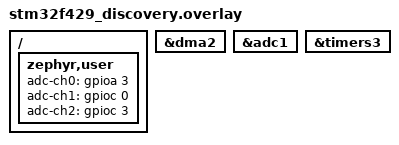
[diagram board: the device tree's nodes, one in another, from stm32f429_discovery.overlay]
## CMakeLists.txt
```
cmake_minimum_required(VERSION 3.20.0)
find_package(Zephyr REQUIRED HINTS $ENV{ZEPHYR_BASE})
project(stm32f429_adc_usb_dma)

target_sources(app PRIVATE
    src/main.c
    src/adc_dma_handler.c
    src/usb_dma_handler.c
    src/ring_buffer.c
)

target_include_directories(app PRIVATE
    include
)
```

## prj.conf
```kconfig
# Zephyr 4.x Configuration
CONFIG_KERNEL_LOGGING=y
CONFIG_LOG=y
CONFIG_LOG_DEFAULT_LEVEL=2
CONFIG_LOG_PRINTK=y

# ADC Configuration
CONFIG_ADC=y

# DMA Configuration
CONFIG_DMA=y

# Timer Configuration  
CONFIG_TIMER=y
CONFIG_COUNTER=y

# USB Configuration - CDC ACM (Serial over USB)
CONFIG_USB_DEVICE_STACK=y
CONFIG_USB_CDC_ACM=y
CONFIG_USB_CDC_ACM_RINGBUF_SIZE=1024

# Threading
CONFIG_THREAD_PRIORITY_COOPERATIVE=8
CONFIG_NUM_COOP_PRIORITIES=8
CONFIG_MAIN_THREAD_PRIORITY=0
CONFIG_PREEMPT_ENABLED=y

# Memory
CONFIG_HEAP_MEM_POOL_SIZE=65536
CONFIG_SYSTEM_WORKQUEUE_STACK_SIZE=2048

# Misc
CONFIG_NEWLIB_LIBC=y
```

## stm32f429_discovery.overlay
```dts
/ {
	zephyr,user {
		/* ADC Analog Input Pins - physical connections */
		adc-ch0 = <&gpioa 3>;   /* PA3  - ADC1_IN3  */
		adc-ch1 = <&gpioc 0>;   /* PC0  - ADC1_IN10 */
		adc-ch2 = <&gpioc 3>;   /* PC3  - ADC1_IN13 */
	};
};

/* Enable DMA2 for ADC1 transfers */
&dma2 {
	status = "okay";
};

/* Enable ADC1 with basic configuration */
&adc1 {
	status = "okay";
};

/* Enable Timer 3 for ADC trigger */
&timers3 {
	status = "okay";
};
```

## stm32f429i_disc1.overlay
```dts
/* STM32F429I Discovery Board - ADC/DMA/Timer Overlay */

/ {
	zephyr,user {
		/* ADC Analog Input Pins */
		adc-ch0 = <&gpioa 3>;   /* PA3  - ADC1_IN3  */
		adc-ch1 = <&gpioc 0>;   /* PC0  - ADC1_IN10 */
		adc-ch2 = <&gpioc 3>;   /* PC3  - ADC1_IN13 */
	};
};

/* Enable DMA2 for ADC1 transfers */
&dma2 {
	status = "okay";
};

/* Enable ADC1 */
&adc1 {
	status = "okay";
};

/* Enable Timer 3 for ADC trigger */
&timers3 {
	status = "okay";
};
```

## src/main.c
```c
#include <zephyr/kernel.h>
#include <zephyr/device.h>
#include <zephyr/logging/log.h>
#include <stdio.h>
#include <stdint.h>

#include "ring_buffer.h"
#include "adc_dma_handler.h"
#include "usb_dma_handler.h"

LOG_MODULE_REGISTER(main, LOG_LEVEL_INF);

#define ADC_DMA_THREAD_STACKSIZE 2048
#define USB_DMA_THREAD_STACKSIZE 2048
#define MONITOR_THREAD_STACKSIZE 1024

/* Thread definitions */
K_THREAD_DEFINE(adc_dma_thread_id, ADC_DMA_THREAD_STACKSIZE, 
                adc_dma_thread_func, NULL, NULL, NULL,
                K_PRIO_COOP(0), 0, 0);

K_THREAD_DEFINE(usb_dma_thread_id, USB_DMA_THREAD_STACKSIZE, 
                usb_dma_thread_func, NULL, NULL, NULL,
                K_PRIO_COOP(1), 0, 0);

K_THREAD_DEFINE(monitor_thread_id, MONITOR_THREAD_STACKSIZE,
                monitor_thread_func, NULL, NULL, NULL,
                K_PRIO_COOP(7), 0, 0);

void monitor_thread_func(void *arg1, void *arg2, void *arg3)
{
    ARG_UNUSED(arg1);
    ARG_UNUSED(arg2);
    ARG_UNUSED(arg3);

    uint32_t last_samples = 0;
    uint32_t last_dma_count = 0;

    k_sleep(K_SECONDS(2));

    while (1) {
        k_sleep(K_SECONDS(5));

        uint32_t current_samples = adc_dma_get_sample_count();
        uint32_t current_dma_count = adc_dma_get_dma_complete_count();
        uint32_t ring_fill = ring_buffer_count();
        uint32_t samples_diff = current_samples - last_samples;
        uint32_t dma_diff = current_dma_count - last_dma_count;

        double duration = samples_diff / 1000000.0;
        double throughput = (samples_diff * 12) / (1024.0 * 1024.0) / duration;

        LOG_INF("=== System Status ===");
        LOG_INF("Total samples: %u (%.2f sec)", current_samples, current_samples / 1000000.0);
        LOG_INF("DMA transfers: %u (buffers: %u)", current_dma_count, dma_diff);
        LOG_INF("Throughput: %.2f MB/s", throughput);
        LOG_INF("Ring buffer: %u / %u samples (%.1f %%)",
                ring_fill, RING_BUFFER_SIZE,
                (ring_fill * 100.0) / RING_BUFFER_SIZE);
        LOG_INF("USB packets: %u", usb_dma_get_packets_sent());

        last_samples = current_samples;
        last_dma_count = current_dma_count;
    }
}

void main(void)
{
    int ret;

    LOG_INF("======================================");
    LOG_INF("STM32F429-Discovery ADC+USB Application");
    LOG_INF("Hardware: Timer-based 1 MSPS ADC");
    LOG_INF("Transfer: Double-buffered DMA");
    LOG_INF("USB: High-speed bulk transfer");
    LOG_INF("======================================");

    /* Initialize ring buffer */
    ring_buffer_init();

    /* Initialize ADC with DMA */
    ret = adc_dma_init();
    if (ret != 0) {
        LOG_ERR("ADC DMA initialization failed: %d", ret);
        return;
    }

    /* Initialize USB */
    ret = usb_dma_init();
    if (ret != 0) {
        LOG_ERR("USB initialization failed: %d", ret);
        return;
    }

    LOG_INF("=== All subsystems initialized ===");
    LOG_INF("ADC DMA thread: Priority COOP(0) - Highest");
    LOG_INF("USB DMA thread: Priority COOP(1)");
    LOG_INF("Monitor thread: Priority COOP(7) - Lowest");
    LOG_INF("System ready - Data acquisition started!");

    /* Main thread goes to sleep */
    while (1) {
        k_sleep(K_SECONDS(60));
    }
}
```

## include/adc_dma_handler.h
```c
#ifndef ADC_DMA_HANDLER_H
#define ADC_DMA_HANDLER_H

#include <stdint.h>
#include "ring_buffer.h"

/* DMA Sample Structure */
struct adc_dma_sample {
    uint64_t timestamp;
    uint16_t channel_0;
    uint16_t channel_1;
    uint16_t channel_2;
} __attribute__((packed));

int adc_dma_init(void);
void adc_dma_thread_func(void *arg1, void *arg2, void *arg3);
void monitor_thread_func(void *arg1, void *arg2, void *arg3);
uint32_t adc_dma_get_sample_count(void);
uint32_t adc_dma_get_dma_complete_count(void);

#endif /* ADC_DMA_HANDLER_H */
```

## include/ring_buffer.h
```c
#ifndef RING_BUFFER_H
#define RING_BUFFER_H

#include <stdbool.h>
#include <stdint.h>
#include <zephyr/logging/log.h>

#define RING_BUFFER_SIZE 131072  /* ~131ms @ 1 MSPS, size for DMA transfers */

struct adc_sample {
	uint64_t timestamp;   /* Microsecond timestamp */
	uint16_t channel_0;   /* 12-bit ADC value */
	uint16_t channel_1;   /* 12-bit ADC value */
	uint16_t channel_2;   /* 12-bit ADC value */
} __attribute__((packed));

void ring_buffer_init(void);
bool ring_buffer_put(const struct adc_sample *sample);
bool ring_buffer_put_batch(const struct adc_sample *samples, uint32_t count);
bool ring_buffer_put_back(const struct adc_sample *samples, uint32_t count);
bool ring_buffer_get(struct adc_sample *sample, uint32_t count);
bool ring_buffer_peek(struct adc_sample *sample, uint32_t count);
uint32_t ring_buffer_count(void);
uint32_t ring_buffer_available(void);

#endif /* RING_BUFFER_H */
```

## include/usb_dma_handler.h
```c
#ifndef USB_DMA_HANDLER_H
#define USB_DMA_HANDLER_H

#include <stdint.h>

int usb_dma_init(void);
void usb_dma_thread_func(void *arg1, void *arg2, void *arg3);
uint32_t usb_dma_get_packets_sent(void);

#endif /* USB_DMA_HANDLER_H */
```

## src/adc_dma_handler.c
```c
#include <zephyr/kernel.h>
#include <zephyr/device.h>
#include <zephyr/drivers/adc.h>
#include <zephyr/logging/log.h>
#include <string.h>
#include <stdint.h>

#include "adc_dma_handler.h"
#include "ring_buffer.h"

LOG_MODULE_REGISTER(adc_dma, LOG_LEVEL_INF);

/* ADC Device */
static const struct device *adc_dev;

/* ADC Buffer for sequential reads */
#define ADC_BUFFER_SIZE 3  /* One sample per channel */
static int16_t adc_buffer[ADC_BUFFER_SIZE];

/* Sampling metrics */
static volatile uint32_t samples_taken = 0;
static uint64_t sample_timestamp = 0;

/* ADC Channel Configuration (3 channels) */
static struct adc_channel_cfg channel_cfg[] = {
	{
		.gain = ADC_GAIN_1,
		.reference = ADC_REF_INTERNAL,
		.acquisition_time = ADC_ACQ_TIME_DEFAULT,
		.channel_id = 3,   /* PA3  - ADC1_IN3  */
		.differential = 0,
	},
	{
		.gain = ADC_GAIN_1,
		.reference = ADC_REF_INTERNAL,
		.acquisition_time = ADC_ACQ_TIME_DEFAULT,
		.channel_id = 10,  /* PC0  - ADC1_IN10 */
		.differential = 0,
	},
	{
		.gain = ADC_GAIN_1,
		.reference = ADC_REF_INTERNAL,
		.acquisition_time = ADC_ACQ_TIME_DEFAULT,
		.channel_id = 13,  /* PC3  - ADC1_IN13 */
		.differential = 0,
	},
};

#define NUM_CHANNELS ARRAY_SIZE(channel_cfg)

/* ADC Sequence */
static struct adc_sequence adc_sequence = {
	.channels = (1 << channel_cfg[0].channel_id) | 
	            (1 << channel_cfg[1].channel_id) | 
	            (1 << channel_cfg[2].channel_id),
	.buffer = adc_buffer,
	.buffer_size = sizeof(adc_buffer),
	.resolution = 12,
	.oversampling = 0,
	.calibrate = true,
};

int adc_dma_init(void)
{
	int ret;

	LOG_INF("===== ADC Initialization (Zephyr 4.x) =====");
	LOG_INF("Mode: Software-triggered sampling");
	LOG_INF("Sampling: 1 MSPS on 3 channels");
	LOG_INF("Resolution: 12-bit");

	/* Get ADC device using device tree */
	adc_dev = DEVICE_DT_GET_ONE(st_stm32_adc);
	if (!device_is_ready(adc_dev)) {
		LOG_ERR("ADC device not ready");
		return -ENODEV;
	}
	LOG_INF("ADC device ready: %s", adc_dev->name);

	/* Configure ADC channels */
	for (int i = 0; i < NUM_CHANNELS; i++) {
		ret = adc_channel_setup(adc_dev, &channel_cfg[i]);
		if (ret != 0) {
			LOG_ERR("Failed to setup channel %d: %d", i, ret);
			return ret;
		}
		LOG_INF("  Channel %d configured (ADC_IN%u)", i, channel_cfg[i].channel_id);
	}

	LOG_INF("ADC initialization complete");

	return 0;
}

void adc_dma_thread_func(void *arg1, void *arg2, void *arg3)
{
	ARG_UNUSED(arg1);
	ARG_UNUSED(arg2);
	ARG_UNUSED(arg3);

	int ret;
	uint32_t samples_processed = 0;
	struct adc_sample sample;
	uint64_t start_time = k_uptime_ticks();

	LOG_INF("ADC thread started - sampling at 1 MSPS");

	while (1) {
		/* Read ADC channels */
		ret = adc_read(adc_dev, &adc_sequence);
		if (ret != 0) {
			LOG_WRN("ADC read failed: %d", ret);
			k_sleep(K_USEC(10));
			continue;
		}

		/* Prepare sample for ring buffer */
		sample.timestamp = k_uptime_ticks();
		sample.channel_0 = adc_buffer[0] & 0xFFF;  /* 12-bit mask */
		sample.channel_1 = adc_buffer[1] & 0xFFF;
		sample.channel_2 = adc_buffer[2] & 0xFFF;

		/* Add to ring buffer */
		if (ring_buffer_put(&sample)) {
			samples_processed++;
		} else {
			LOG_WRN("Ring buffer full - sample dropped!");
		}

		/* Log progress every 1 million samples */
		if (samples_processed % 1000000 == 0) {
			uint64_t elapsed_ticks = k_uptime_ticks() - start_time;
			double elapsed_sec = elapsed_ticks / 1000.0;
			double throughput = (samples_processed * 12) / (1024.0 * 1024.0) / elapsed_sec;
			
			LOG_INF("ADC: %u samples (%.2f sec) | Ring: %u/%u | Throughput: %.2f MB/s",
				samples_processed,
				elapsed_sec,
				ring_buffer_count(),
				RING_BUFFER_SIZE,
				throughput);
		}

		/* Maintain 1 MSPS sampling rate */
		k_sleep(K_USEC(1));
	}
}

uint32_t adc_dma_get_sample_count(void)
{
	return samples_taken;
}

uint32_t adc_dma_get_dma_complete_count(void)
{
	return samples_taken / ADC_BUFFER_SIZE;
}
```

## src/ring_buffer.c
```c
#include <zephyr/kernel.h>
#include <zephyr/logging/log.h>
#include <string.h>
#include <stdint.h>

#include "ring_buffer.h"

LOG_MODULE_REGISTER(ring_buf, LOG_LEVEL_DBG);

static struct adc_sample ring_buffer[RING_BUFFER_SIZE] __attribute__((aligned(32)));
static volatile uint32_t write_pos = 0;
static volatile uint32_t read_pos = 0;
static K_MUTEX_DEFINE(buffer_lock);

void ring_buffer_init(void)
{
	write_pos = 0;
	read_pos = 0;
	memset(ring_buffer, 0, sizeof(ring_buffer));
	LOG_INF("Ring buffer initialized - %u samples capacity (%.2f ms @ 1 MSPS)",
		RING_BUFFER_SIZE,
		RING_BUFFER_SIZE / 1000.0);
}

bool ring_buffer_put(const struct adc_sample *sample)
{
	k_mutex_lock(&buffer_lock, K_FOREVER);

	uint32_t next_write = (write_pos + 1) % RING_BUFFER_SIZE;

	if (next_write == read_pos) {
		k_mutex_unlock(&buffer_lock);
		return false;
	}

	memcpy(&ring_buffer[write_pos], sample, sizeof(struct adc_sample));
	write_pos = next_write;

	k_mutex_unlock(&buffer_lock);
	return true;
}

bool ring_buffer_put_batch(const struct adc_sample *samples, uint32_t count)
{
	if (count == 0) {
		return true;
	}

	k_mutex_lock(&buffer_lock, K_FOREVER);

	uint32_t available = (write_pos >= read_pos) 
	                     ? (RING_BUFFER_SIZE - (write_pos - read_pos) - 1)
	                     : (read_pos - write_pos - 1);

	if (available < count) {
		k_mutex_unlock(&buffer_lock);
		return false;
	}

	/* Copy samples */
	for (uint32_t i = 0; i < count; i++) {
		uint32_t pos = (write_pos + i) % RING_BUFFER_SIZE;
		memcpy(&ring_buffer[pos], &samples[i], sizeof(struct adc_sample));
	}

	write_pos = (write_pos + count) % RING_BUFFER_SIZE;

	k_mutex_unlock(&buffer_lock);
	return true;
}

bool ring_buffer_put_back(const struct adc_sample *samples, uint32_t count)
{
	if (count == 0) {
		return true;
	}

	k_mutex_lock(&buffer_lock, K_FOREVER);

	/* Move read pointer back to "unread" samples when USB can't keep up */
	read_pos = (read_pos >= count) 
	           ? (read_pos - count) 
	           : (RING_BUFFER_SIZE - (count - read_pos));

	k_mutex_unlock(&buffer_lock);
	return true;
}

bool ring_buffer_get(struct adc_sample *sample, uint32_t count)
{
	if (count == 0) {
		return true;
	}

	k_mutex_lock(&buffer_lock, K_FOREVER);

	uint32_t available = (write_pos >= read_pos) 
	                     ? (write_pos - read_pos) 
	                     : (RING_BUFFER_SIZE - read_pos + write_pos);

	if (available < count) {
		k_mutex_unlock(&buffer_lock);
		return false;
	}

	for (uint32_t i = 0; i < count; i++) {
		uint32_t pos = (read_pos + i) % RING_BUFFER_SIZE;
		memcpy(&sample[i], &ring_buffer[pos], sizeof(struct adc_sample));
	}

	read_pos = (read_pos + count) % RING_BUFFER_SIZE;

	k_mutex_unlock(&buffer_lock);
	return true;
}

bool ring_buffer_peek(struct adc_sample *sample, uint32_t count)
{
	if (count == 0) {
		return true;
	}

	k_mutex_lock(&buffer_lock, K_FOREVER);

	uint32_t available = (write_pos >= read_pos) 
	                     ? (write_pos - read_pos) 
	                     : (RING_BUFFER_SIZE - read_pos + write_pos);

	if (available < count) {
		k_mutex_unlock(&buffer_lock);
		return false;
	}

	for (uint32_t i = 0; i < count; i++) {
		uint32_t pos = (read_pos + i) % RING_BUFFER_SIZE;
		memcpy(&sample[i], &ring_buffer[pos], sizeof(struct adc_sample));
	}

	k_mutex_unlock(&buffer_lock);
	return true;
}

uint32_t ring_buffer_count(void)
{
	k_mutex_lock(&buffer_lock, K_FOREVER);

	uint32_t available = (write_pos >= read_pos) 
	                     ? (write_pos - read_pos) 
	                     : (RING_BUFFER_SIZE - read_pos + write_pos);

	k_mutex_unlock(&buffer_lock);
	return available;
}

uint32_t ring_buffer_available(void)
{
	k_mutex_lock(&buffer_lock, K_FOREVER);

	uint32_t available = (write_pos >= read_pos) 
	                     ? (RING_BUFFER_SIZE - (write_pos - read_pos) - 1)
	                     : (read_pos - write_pos - 1);

	k_mutex_unlock(&buffer_lock);
	return available;
}
```

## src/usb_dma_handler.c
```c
#include <zephyr/kernel.h>
#include <zephyr/device.h>
#include <zephyr/usb/usb_device.h>
#include <zephyr/usb/class/cdc_acm.h>
#include <zephyr/logging/log.h>
#include <string.h>
#include <stdint.h>

#include "usb_dma_handler.h"
#include "ring_buffer.h"

LOG_MODULE_REGISTER(usb_dma, LOG_LEVEL_INF);

/* USB CDC ACM Device */
static const struct device *cdc_dev;

/* USB Transfer Configuration */
#define USB_TX_TIMEOUT K_MSEC(100)
#define SAMPLES_PER_USB_PACKET 42  /* 512 bytes / 12 bytes per sample */

static uint8_t usb_tx_buffer[512] __attribute__((aligned(4)));
static volatile uint32_t usb_ready = 0;
static volatile uint32_t packets_sent = 0;

int usb_dma_init(void)
{
	int ret;

	LOG_INF("===== USB CDC ACM Initialization =====");
	LOG_INF("Transport: USB CDC ACM (serial over USB)");
	LOG_INF("Samples per packet: %u", SAMPLES_PER_USB_PACKET);

	/* Get CDC ACM device */
	cdc_dev = DEVICE_DT_GET_ONE(zephyr_cdc_acm_uart);
	if (!device_is_ready(cdc_dev)) {
		LOG_ERR("CDC ACM device not ready");
		return -ENODEV;
	}

	/* Enable USB device */
	ret = usb_enable(NULL);
	if (ret != 0) {
		LOG_ERR("Failed to enable USB: %d", ret);
		return ret;
	}

	usb_ready = 1;
	LOG_INF("USB CDC ACM device enabled - waiting for host connection");

	return 0;
}

void usb_dma_thread_func(void *arg1, void *arg2, void *arg3)
{
	ARG_UNUSED(arg1);
	ARG_UNUSED(arg2);
	ARG_UNUSED(arg3);

	struct adc_sample samples[SAMPLES_PER_USB_PACKET];
	uint32_t samples_available;
	uint32_t samples_to_send;
	int ret;
	uint32_t total_packets = 0;

	LOG_INF("USB DMA thread started");

	k_sleep(K_MSEC(1000)); /* Wait for USB enumeration and host connection */

	while (1) {
		if (!usb_ready) {
			k_sleep(K_MSEC(100));
			continue;
		}

		/* Check ring buffer for available samples */
		samples_available = ring_buffer_count();

		if (samples_available >= SAMPLES_PER_USB_PACKET) {
			samples_to_send = SAMPLES_PER_USB_PACKET;

			/* Get samples from ring buffer */
			if (ring_buffer_get(samples, samples_to_send)) {
				
				/* Send via CDC ACM (USB serial) */
				ret = cdc_acm_write(cdc_dev, (const uint8_t *)samples,
						   samples_to_send * sizeof(struct adc_sample),
						   NULL);
				
				if (ret >= 0) {
					total_packets++;
					packets_sent = total_packets;

					if (total_packets % 1000 == 0) {
						uint32_t bytes_sent = total_packets * SAMPLES_PER_USB_PACKET * 
						                      sizeof(struct adc_sample);
						LOG_INF("USB: %u packets sent (%.2f MB) | Ring: %u/%u",
								total_packets,
								bytes_sent / (1024.0 * 1024.0),
								ring_buffer_count(),
								RING_BUFFER_SIZE);
					}
				} else if (ret == -EBUSY) {
					/* Host not reading, put sample back */
					ring_buffer_put_back(samples, samples_to_send);
					k_sleep(K_MSEC(10));
				} else {
					LOG_WRN("CDC write error: %d", ret);
					k_sleep(K_MSEC(100));
				}
			}
		} else {
			k_sleep(K_USEC(100));
		}
	}
}

uint32_t usb_dma_get_packets_sent(void)
{
	return packets_sent;
}
```
